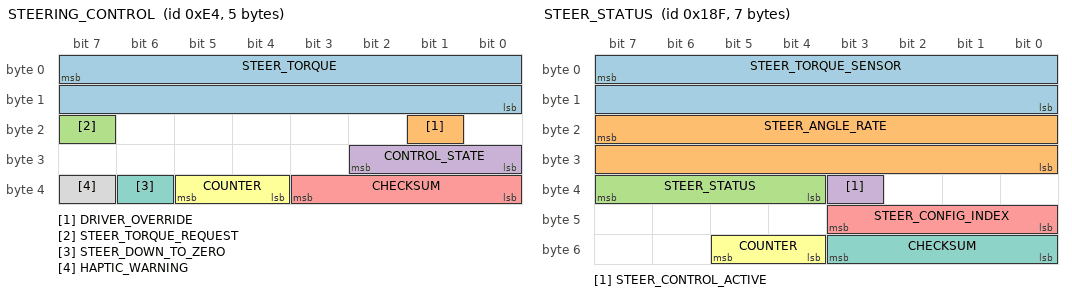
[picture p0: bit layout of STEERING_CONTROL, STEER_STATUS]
BO_ 228 STEERING_CONTROL: 5 ADAS
 SG_ STEER_TORQUE : 7|16@0- (1,0) [-4096|4096] "" EPS
 SG_ DRIVER_OVERRIDE : 17|1@0+ (1,0) [0|1] "" XXX
 SG_ STEER_TORQUE_REQUEST : 23|1@0+ (1,0) [0|1] "" EPS
 SG_ CONTROL_STATE : 26|3@0+ (1,0) [0|7] "" XXX
 SG_ CHECKSUM : 35|4@0+ (1,0) [0|15] "" EPS
 SG_ COUNTER : 37|2@0+ (1,0) [0|3] "" EPS
 SG_ STEER_DOWN_TO_ZERO : 38|1@0+ (1,0) [0|1] "" EPS
 SG_ HAPTIC_WARNING : 39|1@0+ (1,0) [0|1] "" XXX

BO_ 399 STEER_STATUS: 7 EPS
 SG_ STEER_TORQUE_SENSOR : 7|16@0- (-1,0) [-31000|31000] "tbd" EON
 SG_ STEER_ANGLE_RATE : 23|16@0- (-0.1,0) [-31000|31000] "deg/s" EON
 SG_ STEER_STATUS : 39|4@0+ (1,0) [0|15] "" EON
 SG_ STEER_CONTROL_ACTIVE : 35|1@0+ (1,0) [0|1] "" EON
 SG_ STEER_CONFIG_INDEX : 43|4@0+ (1,0) [0|15] "" EON
 SG_ COUNTER : 53|2@0+ (1,0) [0|3] "" EON
 SG_ CHECKSUM : 51|4@0+ (1,0) [0|3] "" EON

CM_ SG_ 228 DRIVER_OVERRIDE "Appears to acknowledge STEER_STATUS.NO_TORQUE_ALERT_1";

VAL_ 228 CONTROL_STATE 0 "init" 1 "standby" 2 "lka_active" 3 "driver_override" 5 "rdm_active";
VAL_ 399 STEER_STATUS 7 "permanent_fault" 6 "tmp_fault" 5 "fault_1" 4 "no_torque_alert_2" 3 "low_speed_lockout" 2 "no_torque_alert_1" 1 "driver_steering" 0 "normal" ;
